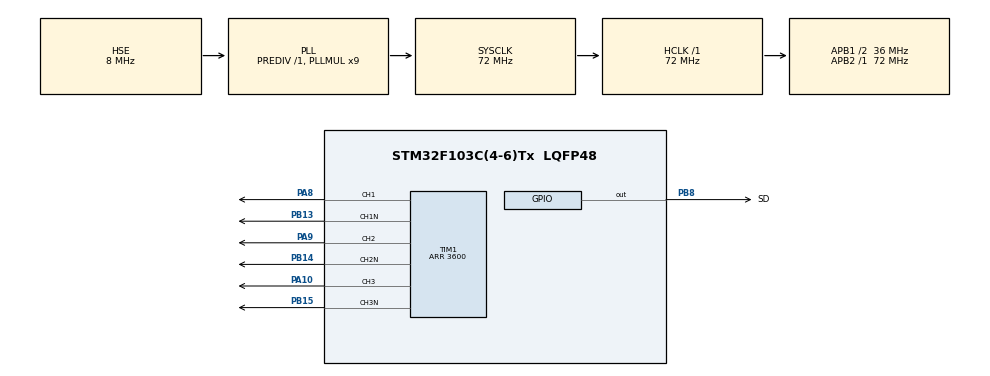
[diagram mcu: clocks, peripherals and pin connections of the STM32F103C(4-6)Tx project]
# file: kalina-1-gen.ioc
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Mcu.Family=STM32F1
Mcu.Name=STM32F103C(4-6)Tx
Mcu.Package=LQFP48
NVIC.PriorityGroup=NVIC_PRIORITYGROUP_4
PA10.Signal=S_TIM1_CH3
PA13.Mode=Serial_Wire
PA13.Signal=SYS_JTMS-SWDIO
PA14.Mode=Serial_Wire
PA14.Signal=SYS_JTCK-SWCLK
PA8.Signal=S_TIM1_CH1
PA9.Signal=S_TIM1_CH2
PB13.Mode=PWM Generation1 CH1 CH1N
PB13.Signal=TIM1_CH1N
PB14.Mode=PWM Generation2 CH2 CH2N
PB14.Signal=TIM1_CH2N
PB15.Mode=PWM Generation3 CH3 CH3N
PB15.Signal=TIM1_CH3N
PB8.GPIO_Label=SD
PB8.Signal=GPIO_Output
PD0-OSC_IN.Mode=HSE-External-Oscillator
PD0-OSC_IN.Signal=RCC_OSC_IN
PD1-OSC_OUT.Mode=HSE-External-Oscillator
PD1-OSC_OUT.Signal=RCC_OSC_OUT
ProjectManager.HeapSize=0x200
ProjectManager.StackSize=0x400
ProjectManager.TargetToolchain=MDK-ARM V5.32
RCC.AHBFreq_Value=72000000
RCC.APB1CLKDivider=RCC_HCLK_DIV2
RCC.APB1Freq_Value=36000000
RCC.APB1TimFreq_Value=72000000
RCC.APB2Freq_Value=72000000
RCC.APB2TimFreq_Value=72000000
RCC.HCLKFreq_Value=72000000
RCC.PLLMUL=RCC_PLL_MUL9
RCC.PLLSourceVirtual=RCC_PLLSOURCE_HSE
RCC.SYSCLKFreq_VALUE=72000000
RCC.SYSCLKSource=RCC_SYSCLKSOURCE_PLLCLK
RCC.USBFreq_Value=72000000
SH.S_TIM1_CH1.0=TIM1_CH1,PWM Generation1 CH1 CH1N
SH.S_TIM1_CH2.0=TIM1_CH2,PWM Generation2 CH2 CH2N
SH.S_TIM1_CH3.0=TIM1_CH3,PWM Generation3 CH3 CH3N
TIM1.Channel-PWM\ Generation1\ CH1\ CH1N=TIM_CHANNEL_1
TIM1.Channel-PWM\ Generation2\ CH2\ CH2N=TIM_CHANNEL_2
TIM1.Channel-PWM\ Generation3\ CH3\ CH3N=TIM_CHANNEL_3
TIM1.DeadTime=36
TIM1.Period=3600
VP_CRC_VS_CRC.Mode=CRC_Activate
VP_TIM1_VS_ClockSourceINT.Mode=Internal
board=custom

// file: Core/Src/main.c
/* USER CODE BEGIN Header */
/**
  ******************************************************************************
  * @file           : main.c
  * @brief          : Main program body
  ******************************************************************************
  * @attention
  *
  * Copyright (c) 2022 STMicroelectronics.
  * All rights reserved.
  *
  * This software is licensed under terms that can be found in the LICENSE file
  * in the root directory of this software component.
  * If no LICENSE file comes with this software, it is provided AS-IS.
  *
  ******************************************************************************
  */
/* USER CODE END Header */
#include "main.h"
#include "crc.h"
#include "tim.h"
#include "gpio.h"

void SystemClock_Config(void);

/* USER CODE BEGIN 0 */
static volatile uint32_t pwm = 0;
/* USER CODE END 0 */

int main(void)
{

  /* MCU Configuration--------------------------------------------------------*/

  /* Reset of all peripherals, Initializes the Flash interface and the Systick. */
  HAL_Init();

  /* Configure the system clock */
  SystemClock_Config();

  /* Initialize all configured peripherals */
  MX_GPIO_Init();
  MX_TIM1_Init();
  MX_CRC_Init();

  /* Infinite loop */
  /* USER CODE BEGIN WHILE */
	TIM1->CCR1 = 0;
	TIM1->CCR2 = 0;
	TIM1->CCR3 = 0;
	//TIM1->CCER=TIM_CCER_CC1E | TIM_CCER_CC1NE | TIM_CCER_CC2E | TIM_CCER_CC2NE | TIM_CCER_CC3E | TIM_CCER_CC3NE;
	HAL_TIM_OC_Start_IT(&htim1, TIM_CHANNEL_4);
	TIM1->CCER = 0x0555;
	TIM1->CR1 = 1;
	//HAL_TIM_PWM_Start(&htim1, TIM_CHANNEL_1);
	//HAL_TIM_PWM_Start(&htim1, TIM_CHANNEL_2);
	//HAL_TIM_PWM_Start(&htim1, TIM_CHANNEL_3);
	HAL_GPIO_WritePin(SD_GPIO_Port, SD_Pin, GPIO_PIN_RESET);
  while (1)
  {
		TIM1->CCR1 = 1800-pwm;
		TIM1->CCR2 = 1800-pwm;
		TIM1->CCR3 = 1800+pwm;

    /* USER CODE END WHILE */

  }
}

void SystemClock_Config(void)
{
  RCC_OscInitTypeDef RCC_OscInitStruct = {0};
  RCC_ClkInitTypeDef RCC_ClkInitStruct = {0};

  /** Initializes the RCC Oscillators according to the specified parameters
  * in the RCC_OscInitTypeDef structure.
  */
  RCC_OscInitStruct.OscillatorType = RCC_OSCILLATORTYPE_HSE;
  RCC_OscInitStruct.HSEState = RCC_HSE_ON;
  RCC_OscInitStruct.HSEPredivValue = RCC_HSE_PREDIV_DIV1;
  RCC_OscInitStruct.HSIState = RCC_HSI_ON;
  RCC_OscInitStruct.PLL.PLLState = RCC_PLL_ON;
  RCC_OscInitStruct.PLL.PLLSource = RCC_PLLSOURCE_HSE;
  RCC_OscInitStruct.PLL.PLLMUL = RCC_PLL_MUL9;
  if (HAL_RCC_OscConfig(&RCC_OscInitStruct) != HAL_OK)
  {
    Error_Handler();
  }

  /** Initializes the CPU, AHB and APB buses clocks
  */
  RCC_ClkInitStruct.ClockType = RCC_CLOCKTYPE_HCLK|RCC_CLOCKTYPE_SYSCLK
                              |RCC_CLOCKTYPE_PCLK1|RCC_CLOCKTYPE_PCLK2;
  RCC_ClkInitStruct.SYSCLKSource = RCC_SYSCLKSOURCE_PLLCLK;
  RCC_ClkInitStruct.AHBCLKDivider = RCC_SYSCLK_DIV1;
  RCC_ClkInitStruct.APB1CLKDivider = RCC_HCLK_DIV2;
  RCC_ClkInitStruct.APB2CLKDivider = RCC_HCLK_DIV1;

  if (HAL_RCC_ClockConfig(&RCC_ClkInitStruct, FLASH_LATENCY_2) != HAL_OK)
  {
    Error_Handler();
  }
}

void Error_Handler(void)
{
  __disable_irq();
  while (1)
  {
  }
}
